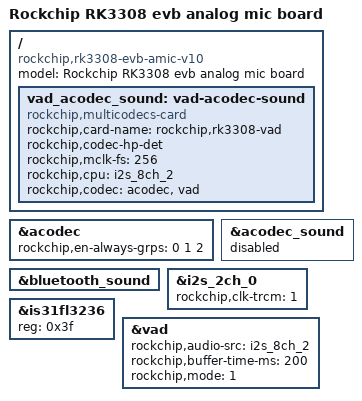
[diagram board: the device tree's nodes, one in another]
/*
 * Copyright (c) 2018 Fuzhou Rockchip Electronics Co., Ltd
 *
 * SPDX-License-Identifier: (GPL-2.0+ OR MIT)
 */

/dts-v1/;

#include "rk3308-evb-v10.dtsi"

/ {
	model = "Rockchip RK3308 evb analog mic board";
	compatible = "rockchip,rk3308-evb-amic-v10", "rockchip,rk3308";

	vad_acodec_sound: vad-acodec-sound {
		status = "okay";
		compatible = "rockchip,multicodecs-card";
		rockchip,card-name = "rockchip,rk3308-vad";
		rockchip,codec-hp-det;
		rockchip,mclk-fs = <256>;
		rockchip,cpu = <&i2s_8ch_2>;
		rockchip,codec = <&acodec>, <&vad>;
	};
};

&acodec {
	rockchip,en-always-grps = <0 1 2>;
};

&acodec_sound {
	status = "disabled";
};

&bluetooth_sound {
	status = "okay";
};

&i2s_2ch_0 {
	status = "okay";
	#sound-dai-cells = <0>;
	rockchip,clk-trcm = <1>;
};

&is31fl3236 {
	reg = <0x3f>;
};

&vad {
	status = "okay";
	rockchip,audio-src = <&i2s_8ch_2>;
	rockchip,buffer-time-ms = <200>;
	rockchip,mode = <1>;
	#sound-dai-cells = <0>;
};
